AUTOSAR XML (schema 00048)
package /SecurityArchitecture/ComponentTypes
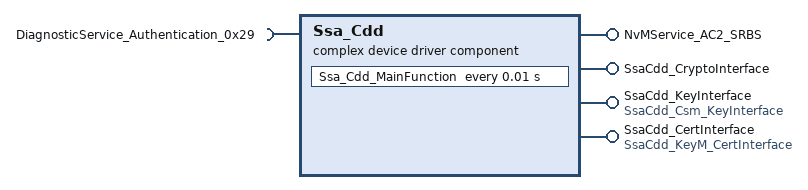
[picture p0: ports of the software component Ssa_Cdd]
  complex device driver sw component type Ssa_Cdd
    4 x provide port:
      NvMService_AC2_SRBS: provided-interface=NvMService_AC2_SRBS  # Iterates over all configured blocks and set up correspoding jobs. Acts as fanout from one to many NvM blocks.
        provided-com-specs:
          operation=GetErrorStatus, queue-length=1
          operation=ReadBlock, queue-length=1
          operation=SetRamBlockStatus, queue-length=1
          operation=WriteBlock, queue-length=1
      SsaCdd_CryptoInterface: provided-interface=SsaCdd_CryptoInterface
        provided-com-specs:
          operation=CancelJob, queue-length=1
          operation=SignatureVerify, queue-length=1
          operation=SignatureGenerate, queue-length=1
          operation=SignatureVerify, queue-length=1
          operation=Hash, queue-length=1
      SsaCdd_KeyInterface: provided-interface=SsaCdd_Csm_KeyInterface
        provided-com-specs:
          operation=KeyElementCopy, queue-length=1
          operation=KeyElementGet, queue-length=1
          operation=KeyElementSet, queue-length=1
          operation=KeySetValid, queue-length=1
      SsaCdd_CertInterface: provided-interface=SsaCdd_KeyM_CertInterface
        provided-com-specs:
          operation=CsrElementSet, queue-length=1
          operation=GetCertificate, queue-length=1
          operation=ServiceCertificate, queue-length=1
          operation=SetCertificate, queue-length=1
    require port DiagnosticService_Authentication_0x29: client-com-spec=Authenticate, required-interface=DiagnosticService_Authentication_0x29
    behavior Ssa_Cdd_InternalBehavior
      5 x operation invoked event:
        OIT_Runnable_SsaCdd_CryptoInterface_CancelJob: start-on-event=Ssa_Cdd_Csm_CancelJob, operation=SsaCdd_CryptoInterface.CancelJob
        OIT_SsaCdd_KeyInterface_KeyElementCopy_SsaCdd_KeyInterface_KeyElementCopy: start-on-event=Ssa_Cdd_Csm_KeyElementCopy, operation=SsaCdd_KeyInterface.KeyElementCopy
        OIT_SsaCdd_KeyInterface_KeyElementGet_SsaCdd_KeyInterface_KeyElementGet: start-on-event=Ssa_Cdd_Csm_KeyElementGet, operation=SsaCdd_KeyInterface.KeyElementGet
        OIT_SsaCdd_KeyInterface_KeyElementSet_SsaCdd_KeyInterface_KeyElementSet: start-on-event=Ssa_Cdd_Csm_KeyElementSet, operation=SsaCdd_KeyInterface.KeyElementSet
        OIT_SsaCdd_KeyInterface_KeySetValid_SsaCdd_KeyInterface_KeySetValid: start-on-event=Ssa_Cdd_Csm_KeySetValid, operation=SsaCdd_KeyInterface.KeySetValid
      init event Ssa_Cdd_InitEvent: start-on-event=Ssa_Cdd_Init
      8 x operation invoked event:
        OIT_Ssa_Cdd_NvMService_AC2_SRBS_GetErrorStatus_NvMService_AC2_SRBS_GetErrorStatus: start-on-event=Ssa_Cdd_NvM_GetErrorStatus, operation=NvMService_AC2_SRBS.GetErrorStatus
        OIT_Ssa_Cdd_NvMService_AC2_SRBS_ReadBlock_NvMService_AC2_SRBS_ReadBlock: start-on-event=Ssa_Cdd_NvM_ReadBlock, operation=NvMService_AC2_SRBS.ReadBlock
        OIT_Ssa_Cdd_NvMService_AC2_SRBS_SetRamBlockStatus_NvMService_AC2_SRBS_SetRamBlockStatus: start-on-event=Ssa_Cdd_NvM_SetRamBlockStatus, operation=NvMService_AC2_SRBS.SetRamBlockStatus
        OIT_Ssa_Cdd_NvMService_AC2_SRBS_WriteBlock_NvMService_AC2_SRBS_WriteBlock: start-on-event=Ssa_Cdd_NvM_WriteBlock, operation=NvMService_AC2_SRBS.WriteBlock
        OIT_SsaCdd_CertInterface_CsrElementSet_SsaCdd_CertInterface_CsrElementSet: start-on-event=Ssa_Cdd_KeyM_CsrElementSet, operation=SsaCdd_CertInterface.CsrElementSet
        OIT_SsaCdd_CertInterface_GetCertificate_SsaCdd_CertInterface_GetCertificate_1: start-on-event=Ssa_Cdd_KeyM_GetCertificate, operation=SsaCdd_CertInterface.GetCertificate
        OIT_SsaCdd_CertInterface_ServiceCertificate_SsaCdd_CertInterface_ServiceCertificate: start-on-event=Ssa_Cdd_KeyM_ServiceCertificate, operation=SsaCdd_CertInterface.ServiceCertificate
        OIT_SsaCdd_CertInterface_SetCertificate_SsaCdd_CertInterface_SetCertificate_1: start-on-event=Ssa_Cdd_KeyM_SetCertificate, operation=SsaCdd_CertInterface.SetCertificate
      timing event TMT_Ssa_Cdd_MainFunction: start-on-event=Ssa_Cdd_MainFunction, period=0.01
      operation invoked event OIT_SsaCdd_CryptoInterface_SignatureVerify_SsaCdd_CryptoInterface_SignatureVerify: start-on-event=Ssa_Cdd_Csm_SignatureVerify, operation=SsaCdd_CryptoInterface.SignatureVerify
      operation invoked event OIT_SsaCdd_CryptoInterface_Hash_SsaCdd_CryptoInterface_Hash: start-on-event=Ssa_Cdd_Csm_Hash, operation=SsaCdd_CryptoInterface.Hash
      operation invoked event OIT_SsaCdd_CryptoInterface_SignatureGenerate_SsaCdd_CryptoInterface_SignatureGenerate: start-on-event=Ssa_Cdd_Csm_SignatureGenerate, operation=SsaCdd_CryptoInterface.SignatureGenerate
      port-api-options:
        enable-take-address=false, error-handling=NO-TRANSFORMER-ERROR-HANDLING, indirect-api=false, port=NvMService_AC2_SRBS
        enable-take-address=false, error-handling=NO-TRANSFORMER-ERROR-HANDLING, indirect-api=false, port=SsaCdd_KeyInterface
      18 x runnable:
        Ssa_Cdd_Csm_CancelJob: can-be-invoked-concurrently=true
        Ssa_Cdd_Csm_KeyElementCopy: can-be-invoked-concurrently=true
        Ssa_Cdd_Csm_KeyElementGet: can-be-invoked-concurrently=true
        Ssa_Cdd_Csm_KeyElementSet: can-be-invoked-concurrently=true
        Ssa_Cdd_Csm_KeySetValid: can-be-invoked-concurrently=true
        Ssa_Cdd_Csm_SignatureVerify: can-be-invoked-concurrently=true
        Ssa_Cdd_Init
        Ssa_Cdd_NvM_GetErrorStatus: can-be-invoked-concurrently=true
        Ssa_Cdd_NvM_ReadBlock: can-be-invoked-concurrently=true
        Ssa_Cdd_NvM_SetRamBlockStatus: can-be-invoked-concurrently=true
        Ssa_Cdd_NvM_WriteBlock: can-be-invoked-concurrently=true
        Ssa_Cdd_KeyM_CsrElementSet: can-be-invoked-concurrently=true
        Ssa_Cdd_KeyM_GetCertificate: can-be-invoked-concurrently=true
        Ssa_Cdd_KeyM_ServiceCertificate: can-be-invoked-concurrently=true
        Ssa_Cdd_KeyM_SetCertificate: can-be-invoked-concurrently=true
        Ssa_Cdd_MainFunction
          sync call SC_DiagnosticService_Authentication_0x29_Authenticate: operation=DiagnosticService_Authentication_0x29.Authenticate, timeout=0
        Ssa_Cdd_Csm_Hash: can-be-invoked-concurrently=true
        Ssa_Cdd_Csm_SignatureGenerate: can-be-invoked-concurrently=true
  swc implementation Ssa_Cdd_Implementation: behavior=Ssa_Cdd_InternalBehavior
    code-descriptors:
      code Default: artifact-descriptors=autosar-engineering-object=category=SWSRC
